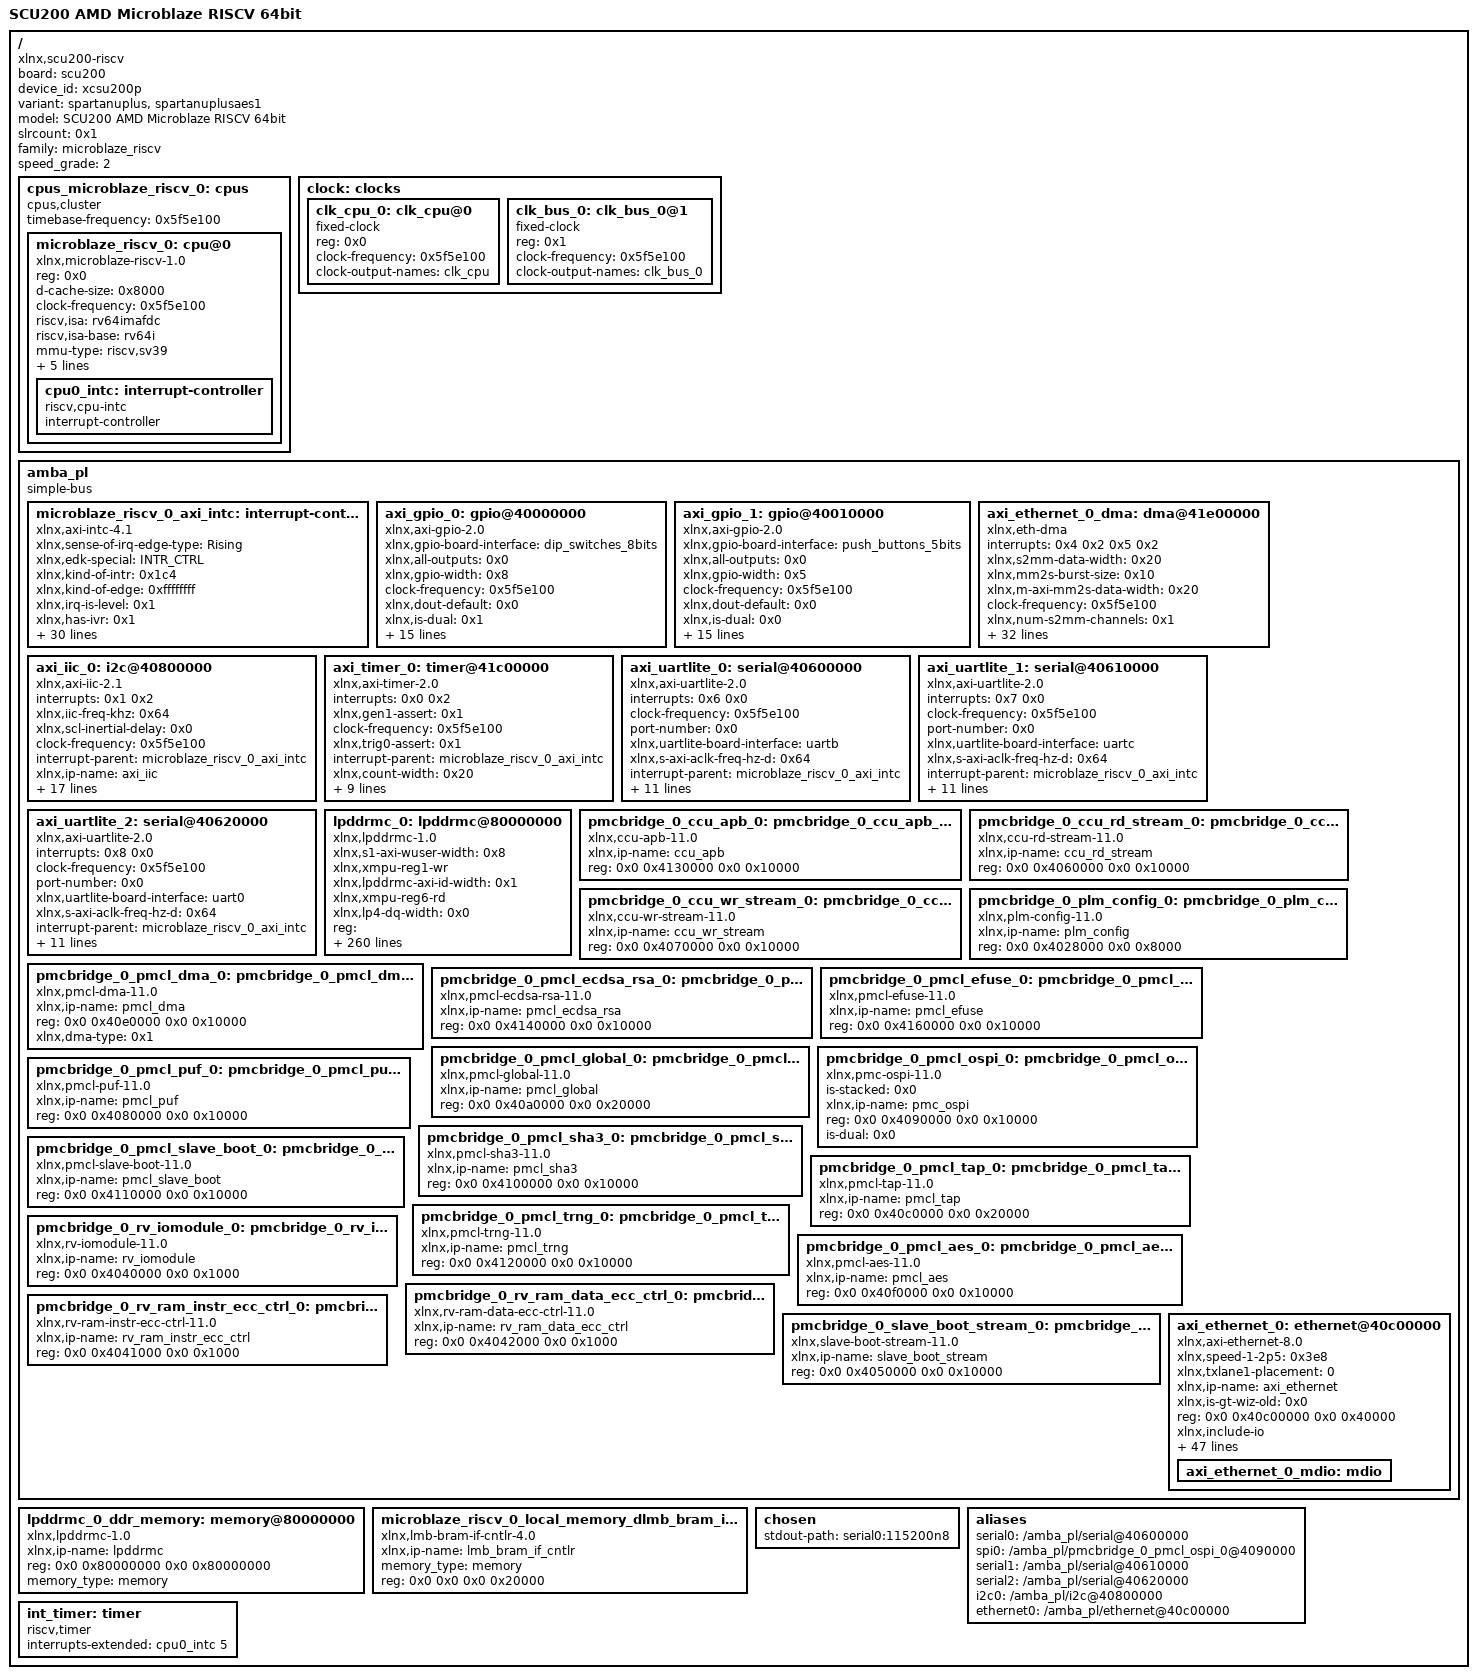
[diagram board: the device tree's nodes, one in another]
/dts-v1/;
/ {
        board = "scu200";
        compatible = "xlnx,scu200-riscv", "qemu,mbv", "amd,mbv";
        device_id = "xcsu200p";
        #address-cells = <0x2>;
        variant = "spartanuplus", "spartanuplusaes1";
        model = "SCU200 AMD Microblaze RISCV 64bit";
        #size-cells = <0x2>;
        slrcount = <0x1>;
        family = "microblaze_riscv";
        speed_grade = "2";

        cpus_microblaze_riscv_0: cpus {
                phandle = <0x25>;
                #cpu-mask-cells = <0x1>;
                compatible = "cpus,cluster";
                #address-cells = <0x1>;
                bootph-all;
                #size-cells = <0x0>;
                #ranges-address-cells = <0x2>;
                #ranges-size-cells = <0x2>;
                timebase-frequency = <0x5f5e100>;

                microblaze_riscv_0: cpu@0 {
                        phandle = <0x26>;
                        reg = <0x0>;
                        d-cache-size = <0x8000>;
                        bootph-all;
                        clock-frequency = <0x5f5e100>;
                        riscv,isa = "rv64imafdc";
                        compatible = "xlnx,microblaze-riscv-1.0", "amd,mbv64", "riscv", "xlnx,microblaze_riscv";
                        riscv,isa-base = "rv64i";
                        device_type = "cpu";
                        mmu-type = "riscv,sv39";
                        riscv,isa-extensions = "i", "m", "a", "f", "d", "c", "zicsr", "zifencei", "zicbom", "b", "zba", "zbb", "zbc", "zbs", "zicntr";
                        i-cache-size = <0x8000>;
                        clocks = <&clk_cpu_0>;

                        cpu0_intc: interrupt-controller {
                                phandle = <0x27>;
                                #interrupt-cells = <0x1>;
                                compatible = "riscv,cpu-intc";
                                interrupt-controller;
                        };
                };
        };

        clock: clocks {
                phandle = <0x28>;
                #address-cells = <0x1>;
                #size-cells = <0x0>;

                clk_cpu_0: clk_cpu@0 {
                        phandle = <0x23>;
                        compatible = "fixed-clock";
                        reg = <0x0>;
                        clock-frequency = <0x5f5e100>;
                        clock-output-names = "clk_cpu";
                        #clock-cells = <0x0>;
                };

                clk_bus_0: clk_bus_0@1 {
                        phandle = <0x24>;
                        compatible = "fixed-clock";
                        reg = <0x1>;
                        clock-frequency = <0x5f5e100>;
                        clock-output-names = "clk_bus_0";
                        #clock-cells = <0x0>;
                };
        };

        amba_pl: amba_pl {
                phandle = <0x22>;
                ranges;
                compatible = "simple-bus";
                #address-cells = <0x2>;
                bootph-all;
                #size-cells = <0x2>;

                microblaze_riscv_0_axi_intc: interrupt-controller@41200000 {
                        phandle = <0x1e>;
                        #interrupt-cells = <0x2>;
                        xlnx,sense-of-irq-edge-type = "Rising";
                        xlnx,edk-special = "INTR_CTRL";
                        xlnx,kind-of-intr = <0x1c4>;
                        xlnx,kind-of-edge = <0xffffffff>;
                        xlnx,irq-is-level = <0x1>;
                        xlnx,has-ivr = <0x1>;
                        compatible = "xlnx,axi-intc-4.1", "xlnx,xps-intc-1.00.a";
                        xlnx,disable-synchronizers = <0x1>;
                        xlnx,kind-of-lvl = <0xffffffff>;
                        xlnx,ivar-reset-value = <0x10>;
                        xlnx,irq-active = <0x1>;
                        xlnx,en-cascade-mode = <0x0>;
                        xlnx,ip-name = "axi_intc";
                        xlnx,has-ilr = <0x0>;
                        reg = <0x0 0x41200000 0x0 0x10000>;
                        xlnx,addr-width = <0x27>;
                        xlnx,s-axi-aclk-freq-mhz = <0x64>;
                        xlnx,num-sw-intr = <0x0>;
                        xlnx,irq-connection = <0x0>;
                        xlnx,num-intr-inputs = <0x9>;
                        xlnx,has-sie = <0x1>;
                        xlnx,enable-async = <0x0>;
                        xlnx,has-cie = <0x1>;
                        xlnx,num-sync-ff = <0x2>;
                        xlnx,edk-iptype = "PERIPHERAL";
                        xlnx,mb-clk-not-connected = <0x1>;
                        xlnx,has-ipr = <0x1>;
                        xlnx,intc-type = <0x0>;
                        xlnx,sense-of-irq-level-type = "Active_High";
                        xlnx,cascade-master = <0x0>;
                        xlnx,processor-clk-freq-mhz = <0x64>;
                        status = "okay";
                        xlnx,is-fast = <0x1>;
                        xlnx,has-fast = <0x1>;
                        xlnx,ivar-rst-val = <0x10>;
                        interrupt-controller;
                        xlnx,async-intr = <0xfffffe0c>;
                        interrupts-extended = <&cpu0_intc 9>;
                };

                axi_gpio_0: gpio@40000000 {
                        phandle = <0x17>;
                        xlnx,gpio-board-interface = "dip_switches_8bits";
                        compatible = "xlnx,axi-gpio-2.0", "xlnx,xps-gpio-1.00.a";
                        xlnx,all-outputs = <0x0>;
                        #gpio-cells = <0x2>;
                        xlnx,gpio-width = <0x8>;
                        clock-frequency = <0x5f5e100>;
                        xlnx,dout-default = <0x0>;
                        xlnx,is-dual = <0x1>;
                        xlnx,ip-name = "axi_gpio";
                        xlnx,tri-default-2 = <0xffffffff>;
                        reg = <0x0 0x40000000 0x0 0x10000>;
                        xlnx,all-inputs-2 = <0x0>;
                        clocks = <&clk_bus_0>;
                        xlnx,all-outputs-2 = <0x1>;
                        gpio-controller;
                        device_type = "gpio";
                        xlnx,interrupt-present = <0x0>;
                        xlnx,gpio2-board-interface = "led_8bits";
                        xlnx,edk-iptype = "PERIPHERAL";
                        xlnx,dout-default-2 = <0x0>;
                        status = "okay";
                        xlnx,gpio2-width = <0x8>;
                        clock-names = "s_axi_aclk";
                        xlnx,use-board-flow;
                        xlnx,tri-default = <0xffffffff>;
                        xlnx,all-inputs = <0x1>;
                };

                axi_gpio_1: gpio@40010000 {
                        phandle = <0x18>;
                        xlnx,gpio-board-interface = "push_buttons_5bits";
                        compatible = "xlnx,axi-gpio-2.0", "xlnx,xps-gpio-1.00.a";
                        xlnx,all-outputs = <0x0>;
                        #gpio-cells = <0x2>;
                        xlnx,gpio-width = <0x5>;
                        clock-frequency = <0x5f5e100>;
                        xlnx,dout-default = <0x0>;
                        xlnx,is-dual = <0x0>;
                        xlnx,ip-name = "axi_gpio";
                        xlnx,tri-default-2 = <0xffffffff>;
                        reg = <0x0 0x40010000 0x0 0x10000>;
                        xlnx,all-inputs-2 = <0x0>;
                        clocks = <&clk_bus_0>;
                        xlnx,all-outputs-2 = <0x0>;
                        gpio-controller;
                        device_type = "gpio";
                        xlnx,interrupt-present = <0x0>;
                        xlnx,gpio2-board-interface = "Custom";
                        xlnx,edk-iptype = "PERIPHERAL";
                        xlnx,dout-default-2 = <0x0>;
                        status = "okay";
                        xlnx,gpio2-width = <0x20>;
                        clock-names = "s_axi_aclk";
                        xlnx,use-board-flow;
                        xlnx,tri-default = <0xffffffff>;
                        xlnx,all-inputs = <0x1>;
                };

                axi_ethernet_0_dma: dma@41e00000 {
                        phandle = <0x20>;
                        interrupts = <0x4 0x2 0x5 0x2>;
                        compatible = "xlnx,eth-dma";
                        xlnx,s2mm-data-width = <0x20>;
                        xlnx,mm2s-burst-size = <0x10>;
                        xlnx,m-axi-mm2s-data-width = <0x20>;
                        clock-frequency = <0x5f5e100>;
                        xlnx,num-s2mm-channels = <0x1>;
                        xlnx,dlytmr-resolution = <0x7d>;
                        axistream-control-connected = <&axi_ethernet_0>;
                        interrupt-parent = <&microblaze_riscv_0_axi_intc>;
                        xlnx,sg-length-width = <0x10>;
                        xlnx,prmry-is-aclk-async = <0x0>;
                        xlnx,include-s2mm-sf = <0x1>;
                        #dma-cells = <0x1>;
                        xlnx,ip-name = "axi_dma";
                        xlnx,single-interface = <0x0>;
                        xlnx,sg-include-stscntrl-strm = <0x1>;
                        xlnx,include-s2mm-dre = <0x1>;
                        reg = <0x0 0x41e00000 0x0 0x10000>;
                        xlnx,addr-width = <0x20>;
                        xlnx,include-s2mm = <0x1>;
                        clocks = <&clk_bus_0>;
                        xlnx,s-axis-s2mm-tdata-width = <0x20>;
                        xlnx,micro-dma = <0x0>;
                        xlnx,increase-throughput = <0x0>;
                        xlnx,mm2s-data-width = <0x20>;
                        xlnx,addrwidth = <0x20>;
                        xlnx,sg-use-stsapp-length = <0x1>;
                        xlnx,m-axis-mm2s-tdata-width = <0x20>;
                        xlnx,include-dre;
                        xlnx,edk-iptype = "PERIPHERAL";
                        xlnx,s2mm-burst-size = <0x10>;
                        xlnx,m-axi-s2mm-data-width = <0x20>;
                        xlnx,num-queues = /bits/ 16 <0x0001>;
                        xlnx,num-mm2s-channels = <0x1>;
                        xlnx,enable-multi-channel = <0x0>;
                        status = "okay";
                        xlnx,include-mm2s-sf = <0x1>;
                        clock-names = "s_axi_lite_aclk";
                        axistream-connected = <&axi_ethernet_0>;
                        interrupt-names = "mm2s_introut", "s2mm_introut";
                        xlnx,include-mm2s = <0x1>;
                        xlnx,include-mm2s-dre = <0x1>;
                };

                axi_iic_0: i2c@40800000 {
                        phandle = <0x1c>;
                        interrupts = <0x1 0x2>;
                        xlnx,iic-freq-khz = <0x64>;
                        compatible = "xlnx,axi-iic-2.1", "xlnx,xps-iic-2.00.a";
                        xlnx,scl-inertial-delay = <0x0>;
                        clock-frequency = <0x5f5e100>;
                        interrupt-parent = <&microblaze_riscv_0_axi_intc>;
                        xlnx,ip-name = "axi_iic";
                        xlnx,disable-setup-violation-check = <0x0>;
                        reg = <0x0 0x40800000 0x0 0x10000>;
                        clocks = <&clk_bus_0>;
                        xlnx,gpo-width = <0x1>;
                        xlnx,s-axi-aclk-freq-hz = <0x5f5e100>;
                        xlnx,edk-iptype = "PERIPHERAL";
                        xlnx,static-timing-reg-width = <0x0>;
                        xlnx,sda-level = <0x1>;
                        status = "okay";
                        xlnx,use-board-flow;
                        xlnx,ten-bit-adr = <0x0>;
                        xlnx,default-value = <0x0>;
                        interrupt-names = "iic2intc_irpt";
                        xlnx,iic-board-interface = "iic";
                        xlnx,timing-reg-width = <0x20>;
                        xlnx,iic-freq = <0x186a0>;
                        xlnx,smbus-pmbus-host = <0x0>;
                        xlnx,axi-aclk-freq-mhz = <0x64>;
                        xlnx,sda-inertial-delay = <0x0>;
                };

                axi_timer_0: timer@41c00000 {
                        phandle = <0x1f>;
                        interrupts = <0x0 0x2>;
                        compatible = "xlnx,axi-timer-2.0", "xlnx,xps-timer-1.00.a";
                        xlnx,gen1-assert = <0x1>;
                        clock-frequency = <0x5f5e100>;
                        xlnx,trig0-assert = <0x1>;
                        interrupt-parent = <&microblaze_riscv_0_axi_intc>;
                        xlnx,count-width = <0x20>;
                        xlnx,ip-name = "axi_timer";
                        xlnx,one-timer-only = <0x0>;
                        reg = <0x0 0x41c00000 0x0 0x10000>;
                        clocks = <&clk_bus_0>;
                        xlnx,gen0-assert = <0x1>;
                        xlnx,mode-64bit = <0x0>;
                        xlnx,edk-iptype = "PERIPHERAL";
                        status = "okay";
                        xlnx,trig1-assert = <0x1>;
                        xlnx,enable-timer2 = <0x1>;
                        interrupt-names = "interrupt";
                };

                axi_uartlite_0: serial@40600000 {
                        phandle = <0x19>;
                        interrupts = <0x6 0x0>;
                        compatible = "xlnx,axi-uartlite-2.0", "xlnx,xps-uartlite-1.00.a";
                        bootph-all;
                        clock-frequency = <0x5f5e100>;
                        port-number = <0x0>;
                        xlnx,uartlite-board-interface = "uartb";
                        xlnx,s-axi-aclk-freq-hz-d = <0x64>;
                        interrupt-parent = <&microblaze_riscv_0_axi_intc>;
                        xlnx,ip-name = "axi_uartlite";
                        reg = <0x0 0x40600000 0x0 0x10000>;
                        xlnx,baudrate = <0x1c200>;
                        clocks = <&clk_bus_0>;
                        current-speed = <0x1c200>;
                        device_type = "serial";
                        xlnx,use-parity = <0x0>;
                        xlnx,edk-iptype = "PERIPHERAL";
                        xlnx,odd-parity = <0x0>;
                        status = "okay";
                        xlnx,use-board-flow;
                        interrupt-names = "interrupt";
                        xlnx,data-bits = <0x8>;
                        xlnx,parity = "No_Parity";
                };

                axi_uartlite_1: serial@40610000 {
                        phandle = <0x1a>;
                        interrupts = <0x7 0x0>;
                        compatible = "xlnx,axi-uartlite-2.0", "xlnx,xps-uartlite-1.00.a";
                        bootph-all;
                        clock-frequency = <0x5f5e100>;
                        port-number = <0x0>;
                        xlnx,uartlite-board-interface = "uartc";
                        xlnx,s-axi-aclk-freq-hz-d = <0x64>;
                        interrupt-parent = <&microblaze_riscv_0_axi_intc>;
                        xlnx,ip-name = "axi_uartlite";
                        reg = <0x0 0x40610000 0x0 0x10000>;
                        xlnx,baudrate = <0x1c200>;
                        clocks = <&clk_bus_0>;
                        current-speed = <0x1c200>;
                        device_type = "serial";
                        xlnx,use-parity = <0x0>;
                        xlnx,edk-iptype = "PERIPHERAL";
                        xlnx,odd-parity = <0x0>;
                        status = "okay";
                        xlnx,use-board-flow;
                        interrupt-names = "interrupt";
                        xlnx,data-bits = <0x8>;
                        xlnx,parity = "No_Parity";
                };

                axi_uartlite_2: serial@40620000 {
                        phandle = <0x1b>;
                        interrupts = <0x8 0x0>;
                        compatible = "xlnx,axi-uartlite-2.0", "xlnx,xps-uartlite-1.00.a";
                        bootph-all;
                        clock-frequency = <0x5f5e100>;
                        port-number = <0x0>;
                        xlnx,uartlite-board-interface = "uart0";
                        xlnx,s-axi-aclk-freq-hz-d = <0x64>;
                        interrupt-parent = <&microblaze_riscv_0_axi_intc>;
                        xlnx,ip-name = "axi_uartlite";
                        reg = <0x0 0x40620000 0x0 0x10000>;
                        xlnx,baudrate = <0x1c200>;
                        clocks = <&clk_bus_0>;
                        current-speed = <0x1c200>;
                        device_type = "serial";
                        xlnx,use-parity = <0x0>;
                        xlnx,edk-iptype = "PERIPHERAL";
                        xlnx,odd-parity = <0x0>;
                        status = "okay";
                        xlnx,use-board-flow;
                        interrupt-names = "interrupt";
                        xlnx,data-bits = <0x8>;
                        xlnx,parity = "No_Parity";
                };

                lpddrmc_0: lpddrmc@80000000 {
                        phandle = <0x21>;
                        xlnx,s1-axi-wuser-width = <0x8>;
                        xlnx,xmpu-reg1-wr;
                        xlnx,lpddrmc-axi-id-width = <0x1>;
                        xlnx,xmpu-reg6-rd;
                        xlnx,lp4-dq-width = <0x0>;
                        reg = <0x0 0x80000000 0x0 0x40000000 0x0 0xc0000000 0x0 0x40000000>;
                        xlnx,ba-width = <0x2>;
                        xlnx,xmpu-reg7-secure-mode = "non_secure";
                        xlnx,lp4-dqs-width = <0x0>;
                        xlnx,xmpu-reg7-size = "None";
                        xlnx,trcd-wr-derate = <0x0>;
                        xlnx,lp4-txcbt-long = <0x0>;
                        xlnx,ilc-size = "1820M";
                        xlnx,lp5-twtr-l = <0x2ee0>;
                        xlnx,xmpu-reg4-size = "None";
                        xlnx,xmpu-reg15-wr;
                        xlnx,lp5-tpdecsodtoff = <0x2e64>;
                        xlnx,lpddrmc-clkfbout-mult = <0x4>;
                        xlnx,xmpu-reg10-secure-mode = "non_secure";
                        xlnx,xmpu-reg1-size = "None";
                        xlnx,twckenl-fs = <0x1>;
                        xlnx,lp4-txcbt-short = <0x0>;
                        xlnx,lp5-twtr-s = <0x1d50>;
                        xlnx,s1-axi-aruser-width = <0xb>;
                        xlnx,xmpu-reg7-wr;
                        xlnx,trdqstfe = <0x88b8>;
                        xlnx,twr = <0x84d0>;
                        xlnx,lpddr5-board-interface = "lpddr5_sdram";
                        xlnx,xmpu-reg13-rd;
                        xlnx,txp = <0x1b58>;
                        xlnx,xmpu-reg8-addr = <0x0>;
                        xlnx,lpddrmc-s0-axi-en;
                        xlnx,rl-set0 = <0xc>;
                        xlnx,rl-set1 = <0xd>;
                        xlnx,xmpu-num-region = <0x0>;
                        xlnx,xmpu-reg6-secure-mode = "non_secure";
                        xlnx,dm-en;
                        xlnx,rl-set2 = <0xe>;
                        xlnx,xmpu-reg5-addr = <0x0>;
                        xlnx,xmpu-reg0-wr;
                        xlnx,tras-derate = <0xab63>;
                        xlnx,xmpu-reg5-rd;
                        xlnx,controllertype = "LPDDR5_SDRAM";
                        xlnx,s1-axi-ruser-width = <0x8>;
                        xlnx,xmpu-reg2-addr = <0x0>;
                        xlnx,tmrd = <0x36b0>;
                        xlnx,trdqstfx = <0x88b8>;
                        xlnx,lp5-ck-width = <0x1>;
                        xlnx,s0-axi-datawidth = <0x100>;
                        xlnx,twlo-max = <0x4e20>;
                        xlnx,lpddr-freq-sel = "SYS_CLK_FROM_MEMORY_CLK";
                        xlnx,lpddrmc-aclk1-freq = <0x64>;
                        xlnx,trefi = <0x3b99d0>;
                        xlnx,xmpu-reg15-size = "None";
                        xlnx,lp5-tpdn = <0x2e64>;
                        xlnx,lpddrmc-vco-freq = <0x3f8b651f>;
                        xlnx,nwr = <0x13>;
                        xlnx,xmpu-reg14-wr;
                        xlnx,xmpu-reg12-size = "None";
                        xlnx,trfcpb = <0x1d4c0>;
                        xlnx,tras = <0xa410>;
                        xlnx,user-refresh = "DISABLE";
                        xlnx,user-xsdb-intf-en;
                        xlnx,tmrr = <0x4>;
                        xlnx,trcd = <0x4650>;
                        xlnx,tccd-l = <0x4>;
                        xlnx,xmpu-reg6-wr;
                        xlnx,tmrw = <0x2710>;
                        xlnx,tccd-s = <0x2>;
                        xlnx,wdqs-off = <0x0>;
                        xlnx,xmpu-reg5-secure-mode = "non_secure";
                        xlnx,lp5-wck-width = <0x4>;
                        xlnx,xmpu-reg12-rd;
                        xlnx,ilc-max-size = "1820M";
                        xlnx,lp5-dmi-width = <0x4>;
                        xlnx,lp5-dq-width = <0x20>;
                        xlnx,periodic-read = "ENABLE";
                        xlnx,tmrri-derate = <0x5c4b>;
                        xlnx,xmpu-reg13-addr = <0x0>;
                        xlnx,xmpu-reg4-rd;
                        xlnx,burst-width = <0x4>;
                        xlnx,xmpu-reg10-addr = <0x0>;
                        xlnx,tckprecs = <0x2a00>;
                        xlnx,twckpre-toggle-rd = <0x6>;
                        xlnx,col-width = <0x6>;
                        xlnx,tdqs = <0x1d5>;
                        xlnx,toscpd = <0x9c40>;
                        xlnx,xmpu-reg9-size = "None";
                        status = "okay";
                        xlnx,system-clock = "Differential";
                        xlnx,xmpu-reg13-wr;
                        xlnx,lp5-tosco-dqi = <0x9c40>;
                        xlnx,s1-axi-datawidth = <0x100>;
                        xlnx,tck = <0x754>;
                        xlnx,xmpu-reg6-size = "None";
                        xlnx,s0-axi-awuser-width = <0xb>;
                        xlnx,ilc-offset = "0M";
                        xlnx,operating-temp = "STANDARD";
                        xlnx,lpddrmc-pll-clkout0-freq = <0xfe2d947>;
                        xlnx,lp4-tckelck = <0x0>;
                        xlnx,trrd-derate = <0x15fb>;
                        xlnx,xmpu-reg4-secure-mode = "non_secure";
                        xlnx,lp5-tosco-dqo = <0x9c40>;
                        xlnx,twlwckoff = <0x36b0>;
                        xlnx,xmpu-reg5-wr;
                        xlnx,xmpu-reg3-size = "None";
                        xlnx,edk-iptype = "PERIPHERAL";
                        xlnx,lpddrmc-tg-1-csv = "no_file_loaded";
                        xlnx,xmpu-reg0-size = "None";
                        xlnx,lp4-cs-width = <0x0>;
                        xlnx,lpddrmc-clkout2-divide = <0x2>;
                        xlnx,xmpu-reg11-rd;
                        xlnx,tfaw = <0x3a98>;
                        xlnx,sys-clk-inputclk0-period = <0x4e2>;
                        xlnx,lpddrmc-config-num = "config6";
                        xlnx,xmpu-reg15-secure-mode = "non_secure";
                        xlnx,trpab = <0x5208>;
                        xlnx,twtr = <0x0>;
                        xlnx,xmpu-reg3-rd;
                        xlnx,xmpu-reg7-addr = <0x0>;
                        xlnx,lp4-ca-width = <0x0>;
                        xlnx,tccd = <0x0>;
                        xlnx,tmrri = <0x54f8>;
                        xlnx,lpddrmc-clkout0-divide = <0x4>;
                        xlnx,xmpu-reg4-addr = <0x0>;
                        xlnx,s0-axi-wuser-width = <0x8>;
                        xlnx,tdq7lck = <0x15fc>;
                        xlnx,lpddrmc-s0-axi-parity = "None";
                        xlnx,row-width = <0xf>;
                        xlnx,xmpu-reg3-secure-mode = "non_secure";
                        xlnx,xmpu-reg1-addr = <0x0>;
                        xlnx,xmpu-reg12-wr;
                        xlnx,rl = <0xc>;
                        xlnx,lpddrmc-aclk0-freq = <0x64>;
                        xlnx,lpddrmc-axi-data-width = <0x100>;
                        xlnx,todton-min = <0x5dc>;
                        xlnx,xmpu-reg14-size = "None";
                        xlnx,tccdmw = <0x10>;
                        xlnx,lpddr-address-map = "NA,NA,NA,NA,NA,NA,NA,NA,NA,RA14,RA13,RA12,RA11,RA10,RA9,RA8,RA7,RA6,RA5,RA4,RA3,RA2,RA1,RA0,BA1,BA0,BG1,BG0,CA5,CA4,CA3,CA2,CA1,CA0,NC,NC,NC,NC,NA,NA";
                        xlnx,txcbt = <0x3d090>;
                        xlnx,s0-axi-aruser-width = <0xb>;
                        xlnx,xmpu-reg4-wr;
                        xlnx,xmpu-reg11-size = "None";
                        xlnx,data-width = <0x20>;
                        xlnx,xmpu-reg9-rd;
                        xlnx,lpddr-pre-def-addr-map = "ROW_BANK_COLUMN";
                        compatible = "xlnx,lpddrmc-1.0";
                        xlnx,lpddrmc-divclk-divide = <0x1>;
                        xlnx,twckpre-toggle-wr = <0x2>;
                        xlnx,memory-density = "2GB";
                        xlnx,trcd-derate = <0x4da3>;
                        xlnx,xmpu-reg14-secure-mode = "non_secure";
                        xlnx,speed-grade = "LPDDR5X-8533";
                        xlnx,xmpu-reg10-rd;
                        xlnx,lp4-dq-per-ch-width = <0x0>;
                        xlnx,lpddrmc-s1-axi-parity = "None";
                        xlnx,lpddr4-board-interface = "Custom";
                        xlnx,lpddrmc-s1-axi-en;
                        xlnx,xmpu-reg2-rd;
                        xlnx,lp5-tcslck = <0x15fc>;
                        xlnx,xmpu-reg15-addr = <0x0>;
                        xlnx,lp4-tcke = <0x0>;
                        xlnx,dram-size = "8Gb";
                        xlnx,xmpu-reg2-secure-mode = "non_secure";
                        xlnx,twckpre-static = <0x3>;
                        xlnx,lpddrmc-pinargs = "CONTROLLERTYPE , LPDDR5_SDRAM , SPEED_GRADE , LPDDR5X-8533 , DATA_WIDTH , 32 , LP4_DQS_WIDTH , 0 , LP5_RDQS_WIDTH , 4 , LP4_DMI_WIDTH , 0 , LP5_DMI_WIDTH , 4 , LP4_CA_WIDTH , 0 , LP5_CA_WIDTH , 7 , ROW_WIDTH , 15 , COL_WIDTH , 6 , BA_WIDTH , 2 , BG_WIDTH , 2 , LP5_CK_WIDTH , 1 , LP5_WCK_WIDTH , 4 , LP4_CK_WIDTH , 0 , LP4_CKE_WIDTH , 0 , LP5_CS_WIDTH , 2 , LP4_CS_WIDTH , 0 , DM_EN , true , SYSTEM_CLOCK , Differential , LP5_DQ_WIDTH , 32 , LP4_DQ_WIDTH , 0 , LP5_RESET_WIDTH , 1 , LP4_RESET_WIDTH , 0 , LPDDRMC_CONFIG_NUM , config6 , WR_DBI , false , RD_DBI , false , LP4_DQ_PER_CH_WIDTH , 0";
                        xlnx,twldqoff = <0x36b0>;
                        xlnx,xmpu-reg12-addr = <0x0>;
                        xlnx,tcbtrtw = <0x4e20>;
                        xlnx,xmpu-reg11-wr;
                        xlnx,s0-axi-ruser-width = <0x8>;
                        xlnx,bg-width = <0x2>;
                        xlnx,twckenl-wr = <0x2>;
                        xlnx,wdqs-on = <0x0>;
                        xlnx,trfcab = <0x33450>;
                        xlnx,twlmrd = <0x36b0>;
                        xlnx,tzqreset = <0xc350>;
                        xlnx,mc-op-tck = <0x4e2>;
                        xlnx,wl = <0x6>;
                        xlnx,xmpu-reg8-size = "None";
                        xlnx,lp5-twck2dq7h = <0x15fc>;
                        xlnx,xmpu-reg3-wr;
                        xlnx,xmpu-reg13-secure-mode = "non_secure";
                        xlnx,xmpu-reg8-rd;
                        xlnx,lp5-cs-width = <0x2>;
                        xlnx,xmpu-reg5-size = "None";
                        xlnx,lp4-dmi-width = <0x0>;
                        xlnx,tdhtrain = <0x15fc>;
                        xlnx,xmpu-reg2-size = "None";
                        xlnx,txsr = <0x3519c>;
                        xlnx,trppb-derate = <0x4da3>;
                        xlnx,xmpu-reg1-secure-mode = "non_secure";
                        xlnx,lpddr-user-defined-address-map = "15RA-2BA-2BG-6CA";
                        xlnx,trbtp = <0xea4>;
                        xlnx,trrd = <0xea8>;
                        xlnx,lp4-tosco = <0x0>;
                        xlnx,lp4-cke-width = <0x0>;
                        xlnx,lp4-txcbt-middle = <0x0>;
                        xlnx,lp5-ca-width = <0x7>;
                        xlnx,ip-name = "lpddrmc";
                        xlnx,lpddrmc-clkoutphy-divide = "VCO_DMC";
                        xlnx,xmpu-reg1-rd;
                        xlnx,xmpu-reg9-wr;
                        xlnx,xmpu-reg9-secure-mode = "non_secure";
                        xlnx,lpddrmc-tg-0-csv = "no_file_loaded";
                        xlnx,nrtp = <0x0>;
                        xlnx,sysclk-board-interface = "default_sysclk1_lpddrmc";
                        xlnx,xmpu-reg9-addr = <0x0>;
                        xlnx,lp5-reset-width = <0x1>;
                        xlnx,bank-arch = "BG";
                        xlnx,xmpu-reg6-addr = <0x0>;
                        xlnx,xmpu-reg10-wr;
                        xlnx,lp5-tdq7hck = <0x15fc>;
                        xlnx,lp4-tescke = <0x0>;
                        xlnx,reg-scrub-intvl = <0x15180>;
                        xlnx,xmpu-reg15-rd;
                        xlnx,xmpu-reg12-secure-mode = "non_secure";
                        xlnx,xmpu-reg3-addr = <0x0>;
                        xlnx,odtlon = <0x3>;
                        xlnx,memory-size = <0x80000000>;
                        xlnx,lp5-tdq7hwck = <0x15fc>;
                        xlnx,trfmab = <0x33450>;
                        xlnx,wl-set = "A";
                        xlnx,xmpu-reg2-wr;
                        xlnx,xmpu-reg0-addr = <0x0>;
                        xlnx,xmpu-reg7-rd;
                        xlnx,xmpu-reg13-size = "None";
                        xlnx,trtp = <0x1d4c>;
                        xlnx,trcd-wr = <0x0>;
                        xlnx,xmpu-reg0-secure-mode = "non_secure";
                        xlnx,lpddrmc-temp-dir-delete;
                        xlnx,xmpu-reg10-size = "None";
                        xlnx,lp4-ck-width = <0x0>;
                        xlnx,twck-int = <0x61a8>;
                        xlnx,xmpu-reg8-secure-mode = "non_secure";
                        xlnx,lpddrmc-reg-adec0 = <0x8>;
                        xlnx,lp5-tcbtwckpre-static = <0x4e20>;
                        xlnx,lpddrmc-reg-adec1 = <0x8>;
                        xlnx,s1-axi-awuser-width = <0xb>;
                        xlnx,lp4-reset-width = <0x0>;
                        xlnx,lpddrmc-reg-adec2 = <0x0>;
                        xlnx,lpddrmc-reg-adec3 = <0x0>;
                        xlnx,scrub-size = <0x1>;
                        xlnx,tckpstcs = <0x1d4c>;
                        xlnx,xmpu-reg0-rd;
                        xlnx,inputclk0-period = <0xea8>;
                        xlnx,xmpu-reg8-wr;
                        xlnx,trpab-derate = <0x595b>;
                        xlnx,lp5-tcspd = <0x2e64>;
                        xlnx,xmpu-reg11-secure-mode = "non_secure";
                        xlnx,lpddrmc-clkout1-divide = <0x6>;
                        xlnx,tzqlat = <0x7530>;
                        xlnx,tdq7lwck = <0x15fc>;
                        xlnx,tsr = <0x3a98>;
                        xlnx,twck2ck = <0xeb>;
                        xlnx,xmpu-reg14-addr = <0x0>;
                        xlnx,lp5-tmrwpd = <0x36b0>;
                        xlnx,xmpu-reg14-rd;
                        xlnx,lp5-rdqs-width = <0x4>;
                        xlnx,nrbtp = <0x2>;
                        xlnx,xmpu-reg11-addr = <0x0>;
                        xlnx,trppb = <0x4650>;
                        xlnx,tdstrain = <0x15fc>;
                };

                pmcbridge_0_ccu_apb_0: pmcbridge_0_ccu_apb_0@4130000 {
                        phandle = <0x14>;
                        compatible = "xlnx,ccu-apb-11.0";
                        status = "okay";
                        xlnx,ip-name = "ccu_apb";
                        reg = <0x0 0x4130000 0x0 0x10000>;
                };

                pmcbridge_0_ccu_rd_stream_0: pmcbridge_0_ccu_rd_stream_0@4060000 {
                        phandle = <0x9>;
                        compatible = "xlnx,ccu-rd-stream-11.0";
                        status = "okay";
                        xlnx,ip-name = "ccu_rd_stream";
                        reg = <0x0 0x4060000 0x0 0x10000>;
                };

                pmcbridge_0_ccu_wr_stream_0: pmcbridge_0_ccu_wr_stream_0@4070000 {
                        phandle = <0xa>;
                        compatible = "xlnx,ccu-wr-stream-11.0";
                        status = "okay";
                        xlnx,ip-name = "ccu_wr_stream";
                        reg = <0x0 0x4070000 0x0 0x10000>;
                };

                pmcbridge_0_plm_config_0: pmcbridge_0_plm_config_0@4028000 {
                        phandle = <0x4>;
                        compatible = "xlnx,plm-config-11.0";
                        status = "okay";
                        xlnx,ip-name = "plm_config";
                        reg = <0x0 0x4028000 0x0 0x8000>;
                };

                pmcbridge_0_pmcl_dma_0: pmcbridge_0_pmcl_dma_0@40e0000 {
                        phandle = <0xf>;
                        compatible = "xlnx,pmcl-dma-11.0", "xlnx,pmc-dma";
                        status = "okay";
                        xlnx,ip-name = "pmcl_dma";
                        reg = <0x0 0x40e0000 0x0 0x10000>;
                        xlnx,dma-type = <0x1>;
                };

                pmcbridge_0_pmcl_ecdsa_rsa_0: pmcbridge_0_pmcl_ecdsa_rsa_0@4140000 {
                        phandle = <0x15>;
                        compatible = "xlnx,pmcl-ecdsa-rsa-11.0";
                        status = "okay";
                        xlnx,ip-name = "pmcl_ecdsa_rsa";
                        reg = <0x0 0x4140000 0x0 0x10000>;
                };

                pmcbridge_0_pmcl_efuse_0: pmcbridge_0_pmcl_efuse_0@4160000 {
                        phandle = <0x16>;
                        compatible = "xlnx,pmcl-efuse-11.0";
                        status = "okay";
                        xlnx,ip-name = "pmcl_efuse";
                        reg = <0x0 0x4160000 0x0 0x10000>;
                };

                pmcbridge_0_pmcl_global_0: pmcbridge_0_pmcl_global_0@40a0000 {
                        phandle = <0xd>;
                        compatible = "xlnx,pmcl-global-11.0";
                        status = "okay";
                        xlnx,ip-name = "pmcl_global";
                        reg = <0x0 0x40a0000 0x0 0x20000>;
                };

                pmcbridge_0_pmcl_ospi_0: pmcbridge_0_pmcl_ospi_0@4090000 {
                        phandle = <0xc>;
                        is-stacked = <0x0>;
                        compatible = "xlnx,pmc-ospi-11.0", "xlnx,pmc-ospi";
                        status = "okay";
                        xlnx,ip-name = "pmc_ospi";
                        reg = <0x0 0x4090000 0x0 0x10000>;
                        is-dual = <0x0>;
                };

                pmcbridge_0_pmcl_puf_0: pmcbridge_0_pmcl_puf_0@4080000 {
                        phandle = <0xb>;
                        compatible = "xlnx,pmcl-puf-11.0";
                        status = "okay";
                        xlnx,ip-name = "pmcl_puf";
                        reg = <0x0 0x4080000 0x0 0x10000>;
                };

                pmcbridge_0_pmcl_sha3_0: pmcbridge_0_pmcl_sha3_0@4100000 {
                        phandle = <0x11>;
                        compatible = "xlnx,pmcl-sha3-11.0";
                        status = "okay";
                        xlnx,ip-name = "pmcl_sha3";
                        reg = <0x0 0x4100000 0x0 0x10000>;
                };

                pmcbridge_0_pmcl_slave_boot_0: pmcbridge_0_pmcl_slave_boot_0@4110000 {
                        phandle = <0x12>;
                        compatible = "xlnx,pmcl-slave-boot-11.0";
                        status = "okay";
                        xlnx,ip-name = "pmcl_slave_boot";
                        reg = <0x0 0x4110000 0x0 0x10000>;
                };

                pmcbridge_0_pmcl_tap_0: pmcbridge_0_pmcl_tap_0@40c0000 {
                        phandle = <0xe>;
                        compatible = "xlnx,pmcl-tap-11.0";
                        status = "okay";
                        xlnx,ip-name = "pmcl_tap";
                        reg = <0x0 0x40c0000 0x0 0x20000>;
                };

                pmcbridge_0_pmcl_trng_0: pmcbridge_0_pmcl_trng_0@4120000 {
                        phandle = <0x13>;
                        compatible = "xlnx,pmcl-trng-11.0";
                        status = "okay";
                        xlnx,ip-name = "pmcl_trng";
                        reg = <0x0 0x4120000 0x0 0x10000>;
                };

                pmcbridge_0_pmcl_aes_0: pmcbridge_0_pmcl_aes_0@40f0000 {
                        phandle = <0x10>;
                        compatible = "xlnx,pmcl-aes-11.0";
                        status = "okay";
                        xlnx,ip-name = "pmcl_aes";
                        reg = <0x0 0x40f0000 0x0 0x10000>;
                };

                pmcbridge_0_rv_iomodule_0: pmcbridge_0_rv_iomodule_0@4040000 {
                        phandle = <0x5>;
                        compatible = "xlnx,rv-iomodule-11.0";
                        status = "okay";
                        xlnx,ip-name = "rv_iomodule";
                        reg = <0x0 0x4040000 0x0 0x1000>;
                };

                pmcbridge_0_rv_ram_data_ecc_ctrl_0: pmcbridge_0_rv_ram_data_ecc_ctrl_0@4042000 {
                        phandle = <0x7>;
                        compatible = "xlnx,rv-ram-data-ecc-ctrl-11.0";
                        status = "okay";
                        xlnx,ip-name = "rv_ram_data_ecc_ctrl";
                        reg = <0x0 0x4042000 0x0 0x1000>;
                };

                pmcbridge_0_rv_ram_instr_ecc_ctrl_0: pmcbridge_0_rv_ram_instr_ecc_ctrl_0@4041000 {
                        phandle = <0x6>;
                        compatible = "xlnx,rv-ram-instr-ecc-ctrl-11.0";
                        status = "okay";
                        xlnx,ip-name = "rv_ram_instr_ecc_ctrl";
                        reg = <0x0 0x4041000 0x0 0x1000>;
                };

                pmcbridge_0_slave_boot_stream_0: pmcbridge_0_slave_boot_stream_0@4050000 {
                        phandle = <0x8>;
                        compatible = "xlnx,slave-boot-stream-11.0";
                        status = "okay";
                        xlnx,ip-name = "slave_boot_stream";
                        reg = <0x0 0x4050000 0x0 0x10000>;
                };

                axi_ethernet_0: ethernet@40c00000 {
                        phandle = <0x1d>;
                        xlnx,speed-1-2p5 = <0x3e8>;
                        xlnx,txlane1-placement = "0";
                        xlnx,ip-name = "axi_ethernet";
                        xlnx,is-gt-wiz-old = <0x0>;
                        reg = <0x0 0x40c00000 0x0 0x40000>;
                        xlnx,include-io;
                        xlnx,rxmem = <0x8000>;
                        xlnx,tx-in-upper-nibble;
                        xlnx,axisclkrate = <0x0>;
                        xlnx,txmem = "0";
                        xlnx,mdio-board-interface = "0";
                        xlnx,phyaddr = <0x1>;
                        xlnx,supportlevel = <0x0>;
                        local-mac-address = [00 0A 23 00 00 00];
                        xlnx,diffclk-board-interface = "0";
                        xlnx,frame-filter;
                        axistream-connected = <&axi_ethernet_0_dma>;
                        xlnx,phyrst-board-interface-dummy-port = "0";
                        interrupt-names = "interrupt", "mac_irq", "mm2s_introut", "s2mm_introut";
                        compatible = "xlnx,axi-ethernet-8.0", "xlnx,axi-ethernet-1.00.a", "xlnx,axi-ethernet-1.00.a";
                        xlnx,gt-type = "0";
                        xlnx,drpclkrate = <0x0>;
                        clock-frequency;
                        axistream-control-connected = <&axi_ethernet_0_dma>;
                        interrupt-parent = <&microblaze_riscv_0_axi_intc>;
                        xlnx,versal-gt-board-flow = <0x0>;
                        device_type = "network";
                        xlnx,num-queues = /bits/ 16 <0x0001>;
                        xlnx,channel-ids = <0x1>;
                        max-speed = <0x3e8>;
                        status = "okay";
                        xlnx,timer-format = <0x0>;
                        xlnx,use-board-flow;
                        xlnx,statistics-width = "0";
                        interrupts = <0x3 0x2 0x2 0x0>;
                        xlnx,gtrefclksrc = "0";
                        xlnx,rxcsum = <0x0>;
                        xlnx,statistics-counters;
                        xlnx,include-dre;
                        xlnx,edk-iptype = "0";
                        xlnx,gtrefclkrate = <0x0>;
                        xlnx,lvdsclkrate = <0x0>;
                        xlnx,number-of-table-entries = <0x0>;
                        xlnx,rxlane0-placement = "0";
                        xlnx,timer-clk-period = <0x0>;
                        xlnx,ethernet-board-interface = "0";
                        xlnx,txlane0-placement = "0";
                        xlnx,gtlocation = "0";
                        phy-mode = "gmii";
                        xlnx,gt-settings = <0x0>;
                        xlnx,clockselection = "0";
                        xlnx,processor-mode;
                        xlnx,txcsum = <0x0>;
                        xlnx,phyrst-board-interface = "0";
                        xlnx,axiliteclkrate = <0x0>;
                        xlnx,rxlane1-placement = "0";

                        axi_ethernet_0_mdio: mdio {
                                phandle = <0x2b>;
                                #address-cells = <0x1>;
                                #size-cells = <0x0>;
                        };
                };
        };

        lpddrmc_0_ddr_memory: memory@80000000 {
                phandle = <0x1>;
                compatible = "xlnx,lpddrmc-1.0";
                xlnx,ip-name = "lpddrmc";
                device_type = "memory";
                reg = <0x0 0x80000000 0x0 0x80000000>;
                memory_type = "memory";
        };

        microblaze_riscv_0_local_memory_dlmb_bram_if_cntlr_memory: sram@0 {
                phandle = <0x2>;
                ranges = <0x0 0x0 0x0 0x0 0x20000>;
                compatible = "xlnx,lmb-bram-if-cntlr-4.0", "mmio-sram";
                #address-cells = <0x2>;
                xlnx,ip-name = "lmb_bram_if_cntlr";
                #size-cells = <0x2>;
                memory_type = "memory";
                reg = <0x0 0x0 0x0 0x20000>;
        };

        chosen {
                stdout-path = "serial0:115200n8";
        };

        aliases {
                serial0 = "/amba_pl/serial@40600000";
                spi0 = "/amba_pl/pmcbridge_0_pmcl_ospi_0@4090000";
                serial1 = "/amba_pl/serial@40610000";
                serial2 = "/amba_pl/serial@40620000";
                i2c0 = "/amba_pl/i2c@40800000";
                ethernet0 = "/amba_pl/ethernet@40c00000";
        };

        __symbols__ {
                cpus_microblaze_riscv_0 = "/cpus_microblaze_riscv@0";
                microblaze_riscv_0 = "/cpus_microblaze_riscv@0/cpu@0";
                cpu0_intc = "/cpus_microblaze_riscv@0/cpu@0/interrupt-controller";
                clock = "/clocks";
                clk_cpu_0 = "/clocks/clk_cpu@0";
                clk_bus_0 = "/clocks/clk_bus_0@1";
                amba_pl = "/amba_pl";
                microblaze_riscv_0_axi_intc = "/amba_pl/interrupt-controller@41200000";
                axi_gpio_0 = "/amba_pl/gpio@40000000";
                axi_gpio_1 = "/amba_pl/gpio@40010000";
                axi_ethernet_0_dma = "/amba_pl/dma@41e00000";
                axi_iic_0 = "/amba_pl/i2c@40800000";
                axi_timer_0 = "/amba_pl/timer@41c00000";
                axi_uartlite_0 = "/amba_pl/serial@40600000";
                axi_uartlite_1 = "/amba_pl/serial@40610000";
                axi_uartlite_2 = "/amba_pl/serial@40620000";
                lpddrmc_0 = "/amba_pl/lpddrmc@80000000";
                pmcbridge_0_ccu_apb_0 = "/amba_pl/pmcbridge_0_ccu_apb_0@4130000";
                pmcbridge_0_ccu_rd_stream_0 = "/amba_pl/pmcbridge_0_ccu_rd_stream_0@4060000";
                pmcbridge_0_ccu_wr_stream_0 = "/amba_pl/pmcbridge_0_ccu_wr_stream_0@4070000";
                pmcbridge_0_plm_config_0 = "/amba_pl/pmcbridge_0_plm_config_0@4028000";
                pmcbridge_0_pmcl_dma_0 = "/amba_pl/pmcbridge_0_pmcl_dma_0@40e0000";
                pmcbridge_0_pmcl_ecdsa_rsa_0 = "/amba_pl/pmcbridge_0_pmcl_ecdsa_rsa_0@4140000";
                pmcbridge_0_pmcl_efuse_0 = "/amba_pl/pmcbridge_0_pmcl_efuse_0@4160000";
                pmcbridge_0_pmcl_global_0 = "/amba_pl/pmcbridge_0_pmcl_global_0@40a0000";
                pmcbridge_0_pmcl_ospi_0 = "/amba_pl/pmcbridge_0_pmcl_ospi_0@4090000";
                pmcbridge_0_pmcl_puf_0 = "/amba_pl/pmcbridge_0_pmcl_puf_0@4080000";
                pmcbridge_0_pmcl_sha3_0 = "/amba_pl/pmcbridge_0_pmcl_sha3_0@4100000";
                pmcbridge_0_pmcl_slave_boot_0 = "/amba_pl/pmcbridge_0_pmcl_slave_boot_0@4110000";
                pmcbridge_0_pmcl_tap_0 = "/amba_pl/pmcbridge_0_pmcl_tap_0@40c0000";
                pmcbridge_0_pmcl_trng_0 = "/amba_pl/pmcbridge_0_pmcl_trng_0@4120000";
                pmcbridge_0_pmcl_aes_0 = "/amba_pl/pmcbridge_0_pmcl_aes_0@40f0000";
                pmcbridge_0_rv_iomodule_0 = "/amba_pl/pmcbridge_0_rv_iomodule_0@4040000";
                pmcbridge_0_rv_ram_data_ecc_ctrl_0 = "/amba_pl/pmcbridge_0_rv_ram_data_ecc_ctrl_0@4042000";
                pmcbridge_0_rv_ram_instr_ecc_ctrl_0 = "/amba_pl/pmcbridge_0_rv_ram_instr_ecc_ctrl_0@4041000";
                pmcbridge_0_slave_boot_stream_0 = "/amba_pl/pmcbridge_0_slave_boot_stream_0@4050000";
                axi_ethernet_0 = "/amba_pl/ethernet@40c00000";
                axi_ethernet_0_mdio = "/amba_pl/ethernet@40c00000/mdio";
                lpddrmc_0_ddr_memory = "/memory@80000000";
                microblaze_riscv_0_local_memory_dlmb_bram_if_cntlr_memory = "/memory@0";
        };

        int_timer: timer {
                compatible = "riscv,timer";
                bootph-all;
                interrupts-extended = <&cpu0_intc 5>;
        };
};
